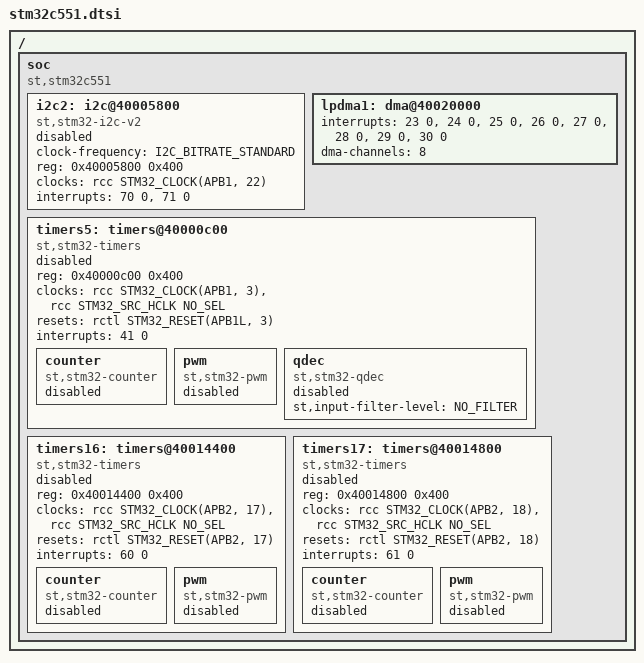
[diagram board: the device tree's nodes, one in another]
/*
 * Copyright (c) 2026 STMicroelectronics
 *
 * SPDX-License-Identifier: Apache-2.0
 */

#include <st/c5/stm32c531.dtsi>

/ {
	soc {
		compatible = "st,stm32c551", "st,stm32c5", "simple-bus";

		i2c2: i2c@40005800 {
			compatible = "st,stm32-i2c-v2";
			clock-frequency = <I2C_BITRATE_STANDARD>;
			#address-cells = <1>;
			#size-cells = <0>;
			reg = <0x40005800 0x400>;
			clocks = <&rcc STM32_CLOCK(APB1, 22)>;
			interrupts = <70 0>, <71 0>;
			interrupt-names = "event", "error";
			status = "disabled";
		};

		lpdma1: dma@40020000 {
			interrupts = <23 0>, <24 0>, <25 0>, <26 0>,
				     <27 0>, <28 0>, <29 0>, <30 0>;
			dma-channels = <8>;
		};

		timers5: timers@40000c00 {
			compatible = "st,stm32-timers";
			reg = <0x40000c00 0x400>;
			clocks = <&rcc STM32_CLOCK(APB1, 3)>,
				 <&rcc STM32_SRC_HCLK NO_SEL>;
			resets = <&rctl STM32_RESET(APB1L, 3)>;
			interrupts = <41 0>;
			interrupt-names = "global";
			status = "disabled";

			counter {
				compatible = "st,stm32-counter";
				status = "disabled";
			};

			pwm {
				compatible = "st,stm32-pwm";
				status = "disabled";
				#pwm-cells = <3>;
			};

			qdec {
				compatible = "st,stm32-qdec";
				st,input-filter-level = <NO_FILTER>;
				status = "disabled";
			};
		};

		timers16: timers@40014400 {
			compatible = "st,stm32-timers";
			reg = <0x40014400 0x400>;
			clocks = <&rcc STM32_CLOCK(APB2, 17)>,
				 <&rcc STM32_SRC_HCLK NO_SEL>;
			resets = <&rctl STM32_RESET(APB2, 17)>;
			interrupts = <60 0>;
			interrupt-names = "global";
			status = "disabled";

			counter {
				compatible = "st,stm32-counter";
				status = "disabled";
			};

			pwm {
				compatible = "st,stm32-pwm";
				status = "disabled";
				#pwm-cells = <3>;
			};
		};

		timers17: timers@40014800 {
			compatible = "st,stm32-timers";
			reg = <0x40014800 0x400>;
			clocks = <&rcc STM32_CLOCK(APB2, 18)>,
				 <&rcc STM32_SRC_HCLK NO_SEL>;
			resets = <&rctl STM32_RESET(APB2, 18)>;
			interrupts = <61 0>;
			interrupt-names = "global";
			status = "disabled";

			counter {
				compatible = "st,stm32-counter";
				status = "disabled";
			};

			pwm {
				compatible = "st,stm32-pwm";
				status = "disabled";
				#pwm-cells = <3>;
			};
		};
	};
};
